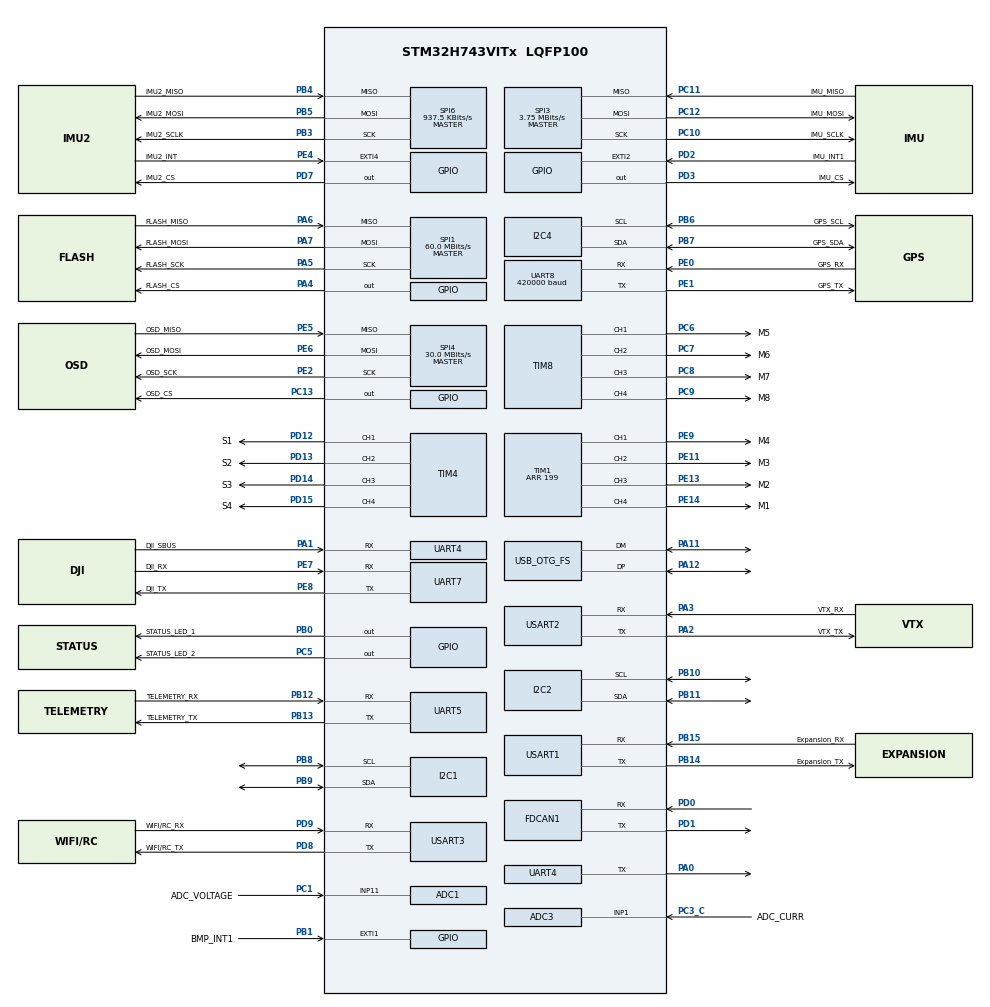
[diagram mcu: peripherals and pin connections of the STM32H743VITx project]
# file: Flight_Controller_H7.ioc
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ADC1.Channel-0\#ChannelRegularConversion=ADC_CHANNEL_11
ADC1.NbrOfConversionFlag=1
ADC1.OffsetNumber-0\#ChannelRegularConversion=ADC_OFFSET_NONE
ADC1.OffsetSignedSaturation-0\#ChannelRegularConversion=DISABLE
ADC1.Rank-0\#ChannelRegularConversion=1
ADC1.SamplingTime-0\#ChannelRegularConversion=ADC_SAMPLETIME_1CYCLE_5
ADC1.master=1
ADC3.Channel-0\#ChannelRegularConversion=ADC_CHANNEL_1
ADC3.NbrOfConversionFlag=1
ADC3.OffsetNumber-0\#ChannelRegularConversion=ADC_OFFSET_NONE
ADC3.OffsetSignedSaturation-0\#ChannelRegularConversion=DISABLE
ADC3.Rank-0\#ChannelRegularConversion=1
ADC3.SamplingTime-0\#ChannelRegularConversion=ADC_SAMPLETIME_1CYCLE_5
CORTEX_M7.default_mode_Activation=1
Dma.Request0=UART8_RX
Dma.Request1=TIM1_CH1
Dma.Request2=TIM1_CH2
Dma.Request3=TIM1_CH3
Dma.Request4=TIM1_CH4
Dma.Request5=TIM1_UP
Dma.TIM1_CH1.1.Direction=DMA_MEMORY_TO_PERIPH
Dma.TIM1_CH1.1.EventEnable=DISABLE
Dma.TIM1_CH1.1.FIFOMode=DMA_FIFOMODE_DISABLE
Dma.TIM1_CH1.1.Instance=DMA1_Stream1
Dma.TIM1_CH1.1.MemDataAlignment=DMA_MDATAALIGN_HALFWORD
Dma.TIM1_CH1.1.MemInc=DMA_MINC_ENABLE
Dma.TIM1_CH1.1.Mode=DMA_NORMAL
Dma.TIM1_CH1.1.PeriphDataAlignment=DMA_PDATAALIGN_HALFWORD
Dma.TIM1_CH1.1.PeriphInc=DMA_PINC_DISABLE
Dma.TIM1_CH1.1.Polarity=HAL_DMAMUX_REQ_GEN_RISING
Dma.TIM1_CH1.1.Priority=DMA_PRIORITY_HIGH
Dma.TIM1_CH1.1.RequestNumber=1
Dma.TIM1_CH1.1.SignalID=NONE
Dma.TIM1_CH1.1.SyncEnable=DISABLE
Dma.TIM1_CH1.1.SyncPolarity=HAL_DMAMUX_SYNC_NO_EVENT
Dma.TIM1_CH1.1.SyncRequestNumber=1
Dma.TIM1_CH1.1.SyncSignalID=NONE
Dma.TIM1_CH2.2.Direction=DMA_MEMORY_TO_PERIPH
Dma.TIM1_CH2.2.EventEnable=DISABLE
Dma.TIM1_CH2.2.FIFOMode=DMA_FIFOMODE_DISABLE
Dma.TIM1_CH2.2.Instance=DMA1_Stream2
Dma.TIM1_CH2.2.MemDataAlignment=DMA_MDATAALIGN_HALFWORD
Dma.TIM1_CH2.2.MemInc=DMA_MINC_ENABLE
Dma.TIM1_CH2.2.Mode=DMA_NORMAL
Dma.TIM1_CH2.2.PeriphDataAlignment=DMA_PDATAALIGN_HALFWORD
Dma.TIM1_CH2.2.PeriphInc=DMA_PINC_DISABLE
Dma.TIM1_CH2.2.Polarity=HAL_DMAMUX_REQ_GEN_RISING
Dma.TIM1_CH2.2.Priority=DMA_PRIORITY_HIGH
Dma.TIM1_CH2.2.RequestNumber=1
Dma.TIM1_CH2.2.SignalID=NONE
Dma.TIM1_CH2.2.SyncEnable=DISABLE
Dma.TIM1_CH2.2.SyncPolarity=HAL_DMAMUX_SYNC_NO_EVENT
Dma.TIM1_CH2.2.SyncRequestNumber=1
Dma.TIM1_CH2.2.SyncSignalID=NONE
Dma.TIM1_CH3.3.Direction=DMA_MEMORY_TO_PERIPH
Dma.TIM1_CH3.3.EventEnable=DISABLE
Dma.TIM1_CH3.3.FIFOMode=DMA_FIFOMODE_DISABLE
Dma.TIM1_CH3.3.Instance=DMA1_Stream3
Dma.TIM1_CH3.3.MemDataAlignment=DMA_MDATAALIGN_HALFWORD
Dma.TIM1_CH3.3.MemInc=DMA_MINC_ENABLE
Dma.TIM1_CH3.3.Mode=DMA_NORMAL
Dma.TIM1_CH3.3.PeriphDataAlignment=DMA_PDATAALIGN_HALFWORD
Dma.TIM1_CH3.3.PeriphInc=DMA_PINC_DISABLE
Dma.TIM1_CH3.3.Polarity=HAL_DMAMUX_REQ_GEN_RISING
Dma.TIM1_CH3.3.Priority=DMA_PRIORITY_HIGH
Dma.TIM1_CH3.3.RequestNumber=1
Dma.TIM1_CH3.3.SignalID=NONE
Dma.TIM1_CH3.3.SyncEnable=DISABLE
Dma.TIM1_CH3.3.SyncPolarity=HAL_DMAMUX_SYNC_NO_EVENT
Dma.TIM1_CH3.3.SyncRequestNumber=1
Dma.TIM1_CH3.3.SyncSignalID=NONE
Dma.TIM1_CH4.4.Direction=DMA_MEMORY_TO_PERIPH
Dma.TIM1_CH4.4.EventEnable=DISABLE
Dma.TIM1_CH4.4.FIFOMode=DMA_FIFOMODE_DISABLE
Dma.TIM1_CH4.4.Instance=DMA1_Stream4
Dma.TIM1_CH4.4.MemDataAlignment=DMA_MDATAALIGN_HALFWORD
Dma.TIM1_CH4.4.MemInc=DMA_MINC_ENABLE
Dma.TIM1_CH4.4.Mode=DMA_NORMAL
Dma.TIM1_CH4.4.PeriphDataAlignment=DMA_PDATAALIGN_HALFWORD
Dma.TIM1_CH4.4.PeriphInc=DMA_PINC_DISABLE
Dma.TIM1_CH4.4.Polarity=HAL_DMAMUX_REQ_GEN_RISING
Dma.TIM1_CH4.4.Priority=DMA_PRIORITY_HIGH
Dma.TIM1_CH4.4.RequestNumber=1
Dma.TIM1_CH4.4.SignalID=NONE
Dma.TIM1_CH4.4.SyncEnable=DISABLE
Dma.TIM1_CH4.4.SyncPolarity=HAL_DMAMUX_SYNC_NO_EVENT
Dma.TIM1_CH4.4.SyncRequestNumber=1
Dma.TIM1_CH4.4.SyncSignalID=NONE
Dma.TIM1_UP.5.Direction=DMA_MEMORY_TO_PERIPH
Dma.TIM1_UP.5.EventEnable=DISABLE
Dma.TIM1_UP.5.FIFOMode=DMA_FIFOMODE_DISABLE
Dma.TIM1_UP.5.Instance=DMA1_Stream5
Dma.TIM1_UP.5.MemDataAlignment=DMA_MDATAALIGN_HALFWORD
Dma.TIM1_UP.5.MemInc=DMA_MINC_ENABLE
Dma.TIM1_UP.5.Mode=DMA_NORMAL
Dma.TIM1_UP.5.PeriphDataAlignment=DMA_PDATAALIGN_HALFWORD
Dma.TIM1_UP.5.PeriphInc=DMA_PINC_DISABLE
Dma.TIM1_UP.5.Polarity=HAL_DMAMUX_REQ_GEN_RISING
Dma.TIM1_UP.5.Priority=DMA_PRIORITY_HIGH
Dma.TIM1_UP.5.RequestNumber=1
Dma.TIM1_UP.5.SignalID=NONE
Dma.TIM1_UP.5.SyncEnable=DISABLE
Dma.TIM1_UP.5.SyncPolarity=HAL_DMAMUX_SYNC_NO_EVENT
Dma.TIM1_UP.5.SyncRequestNumber=1
Dma.TIM1_UP.5.SyncSignalID=NONE
Dma.UART8_RX.0.Direction=DMA_PERIPH_TO_MEMORY
Dma.UART8_RX.0.EventEnable=DISABLE
Dma.UART8_RX.0.FIFOMode=DMA_FIFOMODE_DISABLE
Dma.UART8_RX.0.Instance=DMA1_Stream0
Dma.UART8_RX.0.MemDataAlignment=DMA_MDATAALIGN_BYTE
Dma.UART8_RX.0.MemInc=DMA_MINC_ENABLE
Dma.UART8_RX.0.Mode=DMA_CIRCULAR
Dma.UART8_RX.0.PeriphDataAlignment=DMA_PDATAALIGN_BYTE
Dma.UART8_RX.0.PeriphInc=DMA_PINC_DISABLE
Dma.UART8_RX.0.Polarity=HAL_DMAMUX_REQ_GEN_RISING
Dma.UART8_RX.0.Priority=DMA_PRIORITY_VERY_HIGH
Dma.UART8_RX.0.RequestNumber=1
Dma.UART8_RX.0.SignalID=NONE
Dma.UART8_RX.0.SyncEnable=DISABLE
Dma.UART8_RX.0.SyncPolarity=HAL_DMAMUX_SYNC_NO_EVENT
Dma.UART8_RX.0.SyncRequestNumber=1
Dma.UART8_RX.0.SyncSignalID=NONE
FDCAN1.CalculateBaudRateNominal=166666
FDCAN1.CalculateTimeBitNominal=6000
FDCAN1.CalculateTimeQuantumNominal=2000.0
FDCAN1.Mode=FDCAN_MODE_NORMAL
FDCAN1.RxBuffersNbr=0
FDCAN1.RxFifo0ElmtsNbr=0
FDCAN1.RxFifo1ElmtsNbr=0
FDCAN1.TxBuffersNbr=1
FDCAN1.TxElmtSize=FDCAN_DATA_BYTES_8
FDCAN1.TxFifoQueueElmtsNbr=31
I2C1.Timing=0x107075B0
I2C2.Timing=0x107075B0
I2C4.Timing=0x107075B0
Mcu.Family=STM32H7
Mcu.Name=STM32H743VITx
Mcu.Package=LQFP100
NVIC.DMA1_Stream0_IRQn=true\:0\:0\:false\:false\:true\:false\:true\:true
NVIC.DMA1_Stream1_IRQn=true\:0\:0\:false\:false\:true\:false\:true\:true
NVIC.DMA1_Stream2_IRQn=true\:0\:0\:false\:false\:true\:false\:true\:true
NVIC.DMA1_Stream3_IRQn=true\:0\:0\:false\:false\:true\:false\:true\:true
NVIC.DMA1_Stream4_IRQn=true\:0\:0\:false\:false\:true\:false\:true\:true
NVIC.DMA1_Stream5_IRQn=true\:0\:0\:false\:false\:true\:false\:true\:true
NVIC.OTG_FS_IRQn=true\:0\:0\:false\:false\:true\:false\:true\:true
NVIC.PriorityGroup=NVIC_PRIORITYGROUP_4
NVIC.TIM1_CC_IRQn=true\:0\:0\:false\:false\:true\:true\:true\:true
PA0.Mode=Asynchronous
PA0.PinAttribute=Free
PA0.Signal=UART4_TX
PA1.GPIO_Label=DJI_SBUS
PA1.Mode=Asynchronous
PA1.PinAttribute=Free
PA1.Signal=UART4_RX
PA11.Mode=Device_Only
PA11.PinAttribute=Free
PA11.Signal=USB_OTG_FS_DM
PA12.Mode=Device_Only
PA12.PinAttribute=Free
PA12.Signal=USB_OTG_FS_DP
PA13\ (JTMS/SWDIO).Mode=Serial_Wire
PA13\ (JTMS/SWDIO).PinAttribute=Free
PA13\ (JTMS/SWDIO).Signal=DEBUG_JTMS-SWDIO
PA14\ (JTCK/SWCLK).Mode=Serial_Wire
PA14\ (JTCK/SWCLK).PinAttribute=Free
PA14\ (JTCK/SWCLK).Signal=DEBUG_JTCK-SWCLK
PA2.GPIO_Label=VTX_TX
PA2.Mode=Asynchronous
PA2.PinAttribute=Free
PA2.Signal=USART2_TX
PA3.GPIO_Label=VTX_RX
PA3.Mode=Asynchronous
PA3.PinAttribute=Free
PA3.Signal=USART2_RX
PA4.GPIO_Label=FLASH_CS
PA4.PinAttribute=Free
PA4.Signal=GPIO_Output
PA5.GPIO_Label=FLASH_SCK
PA5.Mode=Full_Duplex_Master
PA5.PinAttribute=Free
PA5.Signal=SPI1_SCK
PA6.GPIO_Label=FLASH_MISO
PA6.Mode=Full_Duplex_Master
PA6.PinAttribute=Free
PA6.Signal=SPI1_MISO
PA7.GPIO_Label=FLASH_MOSI
PA7.Mode=Full_Duplex_Master
PA7.PinAttribute=Free
PA7.Signal=SPI1_MOSI
PB0.GPIO_Label=STATUS_LED_1
PB0.PinAttribute=Free
PB0.PinState=GPIO_PIN_SET
PB0.Signal=GPIO_Output
PB1.GPIO_Label=BMP_INT1
PB1.PinAttribute=Free
PB1.Signal=GPXTI1
PB10.Mode=I2C
PB10.PinAttribute=Free
PB10.Signal=I2C2_SCL
PB11.Mode=I2C
PB11.PinAttribute=Free
PB11.Signal=I2C2_SDA
PB12.GPIO_Label=TELEMETRY_RX
PB12.Mode=Asynchronous
PB12.PinAttribute=Free
PB12.Signal=UART5_RX
PB13.GPIO_Label=TELEMETRY_TX
PB13.Mode=Asynchronous
PB13.PinAttribute=Free
PB13.Signal=UART5_TX
PB14.GPIO_Label=Expansion_TX
PB14.Mode=Asynchronous
PB14.PinAttribute=Free
PB14.Signal=USART1_TX
PB15.GPIO_Label=Expansion_RX
PB15.Mode=Asynchronous
PB15.PinAttribute=Free
PB15.Signal=USART1_RX
PB3\ (JTDO/TRACESWO).GPIO_Label=IMU2_SCLK
PB3\ (JTDO/TRACESWO).Mode=Full_Duplex_Master
PB3\ (JTDO/TRACESWO).PinAttribute=Free
PB3\ (JTDO/TRACESWO).Signal=SPI6_SCK
PB4\ (NJTRST).GPIO_Label=IMU2_MISO
PB4\ (NJTRST).Mode=Full_Duplex_Master
PB4\ (NJTRST).PinAttribute=Free
PB4\ (NJTRST).Signal=SPI6_MISO
PB5.GPIO_Label=IMU2_MOSI
PB5.Mode=Full_Duplex_Master
PB5.PinAttribute=Free
PB5.Signal=SPI6_MOSI
PB6.GPIO_Label=GPS_SCL
PB6.Mode=I2C
PB6.PinAttribute=Free
PB6.Signal=I2C4_SCL
PB7.GPIO_Label=GPS_SDA
PB7.Mode=I2C
PB7.PinAttribute=Free
PB7.Signal=I2C4_SDA
PB8.Mode=I2C
PB8.PinAttribute=Free
PB8.Signal=I2C1_SCL
PB9.Mode=I2C
PB9.PinAttribute=Free
PB9.Signal=I2C1_SDA
PC1.GPIO_Label=ADC_VOLTAGE
PC1.PinAttribute=Free
PC1.Signal=ADCx_INP11
PC10.GPIO_Label=IMU_SCLK
PC10.Mode=Full_Duplex_Master
PC10.PinAttribute=Free
PC10.Signal=SPI3_SCK
PC11.GPIO_Label=IMU_MISO
PC11.Mode=Full_Duplex_Master
PC11.PinAttribute=Free
PC11.Signal=SPI3_MISO
PC12.GPIO_Label=IMU_MOSI
PC12.Mode=Full_Duplex_Master
PC12.PinAttribute=Free
PC12.Signal=SPI3_MOSI
PC13.GPIO_Label=OSD_CS
PC13.PinAttribute=Free
PC13.Signal=GPIO_Output
PC3_C.GPIO_Label=ADC_CURR
PC3_C.Mode=IN1-Single-Ended
PC3_C.PinAttribute=Free
PC3_C.Signal=ADC3_INP1
PC5.GPIO_Label=STATUS_LED_2
PC5.PinAttribute=Free
PC5.PinState=GPIO_PIN_SET
PC5.Signal=GPIO_Output
PC6.GPIO_Label=M5
PC6.PinAttribute=Free
PC6.Signal=S_TIM8_CH1
PC7.GPIO_Label=M6
PC7.PinAttribute=Free
PC7.Signal=S_TIM8_CH2
PC8.GPIO_Label=M7
PC8.PinAttribute=Free
PC8.Signal=S_TIM8_CH3
PC9.GPIO_Label=M8
PC9.PinAttribute=Free
PC9.Signal=S_TIM8_CH4
PD0.Mode=FDCAN_Activate
PD0.PinAttribute=Free
PD0.Signal=FDCAN1_RX
PD1.Mode=FDCAN_Activate
PD1.PinAttribute=Free
PD1.Signal=FDCAN1_TX
PD12.GPIO_Label=S1
PD12.PinAttribute=Free
PD12.Signal=S_TIM4_CH1
PD13.GPIO_Label=S2
PD13.PinAttribute=Free
PD13.Signal=S_TIM4_CH2
PD14.GPIO_Label=S3
PD14.PinAttribute=Free
PD14.Signal=S_TIM4_CH3
PD15.GPIO_Label=S4
PD15.PinAttribute=Free
PD15.Signal=S_TIM4_CH4
PD2.GPIO_Label=IMU_INT1
PD2.PinAttribute=Free
PD2.Signal=GPXTI2
PD3.GPIO_Label=IMU_CS
PD3.PinAttribute=Free
PD3.Signal=GPIO_Output
PD7.GPIO_Label=IMU2_CS
PD7.PinAttribute=Free
PD7.Signal=GPIO_Output
PD8.GPIO_Label=WIFI/RC_TX
PD8.Mode=Asynchronous
PD8.PinAttribute=Free
PD8.Signal=USART3_TX
PD9.GPIO_Label=WIFI/RC_RX
PD9.Mode=Asynchronous
PD9.PinAttribute=Free
PD9.Signal=USART3_RX
PE0.GPIO_Label=GPS_RX
PE0.Mode=Asynchronous
PE0.PinAttribute=Free
PE0.Signal=UART8_RX
PE1.GPIO_Label=GPS_TX
PE1.Mode=Asynchronous
PE1.PinAttribute=Free
PE1.Signal=UART8_TX
PE11.GPIO_Label=M3
PE11.PinAttribute=Free
PE11.Signal=S_TIM1_CH2
PE13.GPIO_Label=M2
PE13.PinAttribute=Free
PE13.Signal=S_TIM1_CH3
PE14.GPIO_Label=M1
PE14.PinAttribute=Free
PE14.Signal=S_TIM1_CH4
PE2.GPIO_Label=OSD_SCK
PE2.Mode=Full_Duplex_Master
PE2.PinAttribute=Free
PE2.Signal=SPI4_SCK
PE4.GPIO_Label=IMU2_INT
PE4.PinAttribute=Free
PE4.Signal=GPXTI4
PE5.GPIO_Label=OSD_MISO
PE5.Mode=Full_Duplex_Master
PE5.PinAttribute=Free
PE5.Signal=SPI4_MISO
PE6.GPIO_Label=OSD_MOSI
PE6.Mode=Full_Duplex_Master
PE6.PinAttribute=Free
PE6.Signal=SPI4_MOSI
PE7.GPIO_Label=DJI_RX
PE7.Mode=Asynchronous
PE7.PinAttribute=Free
PE7.Signal=UART7_RX
PE8.GPIO_Label=DJI_TX
PE8.Mode=Asynchronous
PE8.PinAttribute=Free
PE8.Signal=UART7_TX
PE9.GPIO_Label=M4
PE9.PinAttribute=Free
PE9.Signal=S_TIM1_CH1
PH0-OSC_IN\ (PH0).Mode=HSE-External-Clock-Source
PH0-OSC_IN\ (PH0).PinAttribute=Free
PH0-OSC_IN\ (PH0).Signal=RCC_OSC_IN
ProjectManager.HeapSize=0x200
ProjectManager.StackSize=0x400
ProjectManager.TargetToolchain=STM32CubeIDE
RCC.ADCFreq_Value=76000000
RCC.APB1Freq_Value=60000000
RCC.APB2Freq_Value=60000000
RCC.APB3Freq_Value=120000000
RCC.APB4Freq_Value=60000000
RCC.CortexFreq_Value=240000000
RCC.D2PPRE1=RCC_APB1_DIV2
RCC.D2PPRE2=RCC_APB2_DIV2
RCC.D3PPRE=RCC_APB4_DIV2
RCC.DIVM1=1
RCC.DIVM2=1
RCC.DIVN1=60
RCC.DIVN2=19
RCC.DIVQ1=4
RCC.DIVR1=4
RCC.EnbaleCSS=true
RCC.FDCANCLockSelection=RCC_FDCANCLKSOURCE_HSE
RCC.FLatency-AdvancedSettings=FLASH_LATENCY_0
RCC.HCLKFreq_Value=120000000
RCC.HPRE=RCC_HCLK_DIV2
RCC.HSE_VALUE=8000000
RCC.PLL1_VCI_Range-AdvancedSettings=RCC_PLL1VCIRANGE_0
RCC.PLL1_VCO_SEL-AdvancedSettings=RCC_PLL1VCOMEDIUM
RCC.PLL2FRACN=0
RCC.PLL2_VCI_Range-AdvancedSettings=RCC_PLL2VCIRANGE_0
RCC.PLL2_VCO_SEL-AdvancedSettings=RCC_PLL2VCOMEDIUM
RCC.PLL3_VCI_Range-AdvancedSettings=RCC_PLL3VCIRANGE_0
RCC.PLL3_VCO_SEL-AdvancedSettings=RCC_PLL3VCOMEDIUM
RCC.PLLFRACN=0
RCC.PLLSourceVirtual=RCC_PLLSOURCE_HSE
RCC.PREFETCH_ENABLE=1
RCC.SYSCLKFreq_VALUE=240000000
RCC.SYSCLKSource=RCC_SYSCLKSOURCE_PLLCLK
RCC.USBCLockSelection=RCC_USBCLKSOURCE_HSI48
RCC.USBFreq_Value=48000000
SH.ADCx_INP11.0=ADC1_INP11,IN11-Single-Ended
SH.S_TIM1_CH1.0=TIM1_CH1,PWM Generation1 CH1
SH.S_TIM1_CH2.0=TIM1_CH2,PWM Generation2 CH2
SH.S_TIM1_CH3.0=TIM1_CH3,PWM Generation3 CH3
SH.S_TIM1_CH4.0=TIM1_CH4,PWM Generation4 CH4
SH.S_TIM4_CH1.0=TIM4_CH1,PWM Generation1 CH1
SH.S_TIM4_CH2.0=TIM4_CH2,PWM Generation2 CH2
SH.S_TIM4_CH3.0=TIM4_CH3,PWM Generation3 CH3
SH.S_TIM4_CH4.0=TIM4_CH4,PWM Generation4 CH4
SH.S_TIM8_CH1.0=TIM8_CH1,PWM Generation1 CH1
SH.S_TIM8_CH2.0=TIM8_CH2,PWM Generation2 CH2
SH.S_TIM8_CH3.0=TIM8_CH3,PWM Generation3 CH3
SH.S_TIM8_CH4.0=TIM8_CH4,Output Compare4 CH4
SPI1.BaudRatePrescaler=SPI_BAUDRATEPRESCALER_2
SPI1.CalculateBaudRate=60.0 MBits/s
SPI1.Direction=SPI_DIRECTION_2LINES
SPI1.Mode=SPI_MODE_MASTER
SPI1.VirtualType=VM_MASTER
SPI3.BaudRatePrescaler=SPI_BAUDRATEPRESCALER_32
SPI3.CLKPhase=SPI_PHASE_1EDGE
SPI3.CLKPolarity=SPI_POLARITY_LOW
SPI3.CalculateBaudRate=3.75 MBits/s
SPI3.DataSize=SPI_DATASIZE_8BIT
SPI3.Direction=SPI_DIRECTION_2LINES
SPI3.Mode=SPI_MODE_MASTER
SPI3.VirtualType=VM_MASTER
SPI4.CalculateBaudRate=30.0 MBits/s
SPI4.Direction=SPI_DIRECTION_2LINES
SPI4.Mode=SPI_MODE_MASTER
SPI4.VirtualType=VM_MASTER
SPI6.BaudRatePrescaler=SPI_BAUDRATEPRESCALER_64
SPI6.CLKPhase=SPI_PHASE_2EDGE
SPI6.CLKPolarity=SPI_POLARITY_HIGH
SPI6.CalculateBaudRate=937.5 KBits/s
SPI6.DataSize=SPI_DATASIZE_8BIT
SPI6.Direction=SPI_DIRECTION_2LINES
SPI6.Mode=SPI_MODE_MASTER
SPI6.VirtualType=VM_MASTER
TIM1.Channel-PWM\ Generation1\ CH1=TIM_CHANNEL_1
TIM1.Channel-PWM\ Generation2\ CH2=TIM_CHANNEL_2
TIM1.Channel-PWM\ Generation3\ CH3=TIM_CHANNEL_3
TIM1.Channel-PWM\ Generation4\ CH4=TIM_CHANNEL_4
TIM1.Period=199
TIM4.Channel-PWM\ Generation1\ CH1=TIM_CHANNEL_1
TIM4.Channel-PWM\ Generation2\ CH2=TIM_CHANNEL_2
TIM4.Channel-PWM\ Generation3\ CH3=TIM_CHANNEL_3
TIM4.Channel-PWM\ Generation4\ CH4=TIM_CHANNEL_4
TIM8.Channel-Output\ Compare4\ CH4=TIM_CHANNEL_4
TIM8.Channel-PWM\ Generation1\ CH1=TIM_CHANNEL_1
TIM8.Channel-PWM\ Generation2\ CH2=TIM_CHANNEL_2
TIM8.Channel-PWM\ Generation3\ CH3=TIM_CHANNEL_3
UART4.BaudRate=100000
UART4.Parity=PARITY_EVEN
UART4.RxPinLevelInvertParam=UART_ADVFEATURE_RXINV_ENABLE
UART4.StopBits=UART_STOPBITS_2
UART4.WordLength=WORDLENGTH_9B
UART8.BaudRate=420000
UART8.DMADisableonRxErrorParam=UART_ADVFEATURE_DMA_DISABLEONRXERROR
UART8.OverSampling=UART_OVERSAMPLING_8
UART8.SwapParam=UART_ADVFEATURE_SWAP_DISABLE
USART1.VirtualMode-Asynchronous=VM_ASYNC
USART2.VirtualMode-Asynchronous=VM_ASYNC
USART3.VirtualMode-Asynchronous=VM_ASYNC
USB_DEVICE.CLASS_NAME_FS=CDC
USB_DEVICE.VirtualMode-CDC_FS=Cdc
USB_DEVICE.VirtualModeFS=Cdc_FS
USB_OTG_FS.VirtualMode=Device_Only
VP_ADC3_Vref_Input.Mode=IN-Vrefint
VP_MEMORYMAP_VS_MEMORYMAP.Mode=CurAppReg
VP_TIM1_VS_ClockSourceINT.Mode=Internal
VP_TIM2_VS_ClockSourceINT.Mode=Internal
VP_TIM3_VS_ClockSourceINT.Mode=Internal
VP_TIM4_VS_ClockSourceINT.Mode=Internal
VP_TIM5_VS_ClockSourceINT.Mode=Internal
VP_USB_DEVICE_VS_USB_DEVICE_CDC_FS.Mode=CDC_FS
board=custom

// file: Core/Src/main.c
/* USER CODE BEGIN Header */
/**
  ******************************************************************************
  * @file           : main.c
  * @brief          : Main program body
  ******************************************************************************
  * @attention
  *
  * Copyright (c) 2025 STMicroelectronics.
  * All rights reserved.
  *
  * This software is licensed under terms that can be found in the LICENSE file
  * in the root directory of this software component.
  * If no LICENSE file comes with this software, it is provided AS-IS.
  *
  ******************************************************************************
  */
/* USER CODE END Header */
#include "main.h"
#include "usb_device.h"

/* USER CODE BEGIN Includes */
#include "icm42688p.h"
#include "dshot.h"
#include "motor_mix.h"
#include "crsf.h"
#include "pid.h"
/* USER CODE END Includes */

/* USER CODE BEGIN PD */

/*
 * ── Stick → rate setpoints ───────────────────────────────────────────────────
 * How fast (deg/s) the quad rotates at full stick deflection.
 * Conservative for a first flight — increase after confirming stability.
 */
#define MAX_ROLL_RATE    200.0f
#define MAX_PITCH_RATE   200.0f
#define MAX_YAW_RATE     150.0f

/*
 * ── Gyro axis sign correction ────────────────────────────────────────────────
 * Verify by moving the board and watching gyro values in the debugger.
 * Convention:
 *   Roll board right   → gyro_roll  must be POSITIVE  (flip GYRO_SIGN_ROLL  if not)
 *   Pitch nose up      → gyro_pitch must be POSITIVE  (flip GYRO_SIGN_PITCH if not)
 *   Yaw nose clockwise → gyro_yaw   must be POSITIVE  (flip GYRO_SIGN_YAW   if not)
 */
#define GYRO_SIGN_ROLL    1
#define GYRO_SIGN_PITCH   1
#define GYRO_SIGN_YAW     1

/*
 * ── Arming ───────────────────────────────────────────────────────────────────
 * AUX1 switch must be HIGH and throttle below ARM_THR_MAX for ARM_HOLD_MS
 * before the quad arms. Prevents accidental arming.
 */
#define ARM_THR_MAX       5.0f    /* % throttle ceiling for arming */
#define ARM_HOLD_MS       500U    /* ms to hold conditions before arm */

/*
 * ── PID gains ────────────────────────────────────────────────────────────────
 * D = 0 for first flight. No software gyro LPF yet, so D would amplify noise.
 * Add D (e.g. ROLL_KD 0.000025f) only after P+I is confirmed flyable.
 *
 * If quad oscillates fast  → reduce Kp 20%
 * If quad drifts slowly    → increase Ki 20%
 * If quad feels very lazy  → increase Kp 20%
 */
#define ROLL_KP    0.0015f
#define ROLL_KI    0.002f
#define ROLL_KD    0.0f

#define PITCH_KP   0.0015f
#define PITCH_KI   0.002f
#define PITCH_KD   0.0f

#define YAW_KP     0.0012f
#define YAW_KI     0.004f
#define YAW_KD     0.0f

/* USER CODE END PD */

ADC_HandleTypeDef hadc1;
ADC_HandleTypeDef hadc3;

FDCAN_HandleTypeDef hfdcan1;

I2C_HandleTypeDef hi2c1;
I2C_HandleTypeDef hi2c2;
I2C_HandleTypeDef hi2c4;

SPI_HandleTypeDef hspi1;
SPI_HandleTypeDef hspi3;
SPI_HandleTypeDef hspi4;
SPI_HandleTypeDef hspi6;

TIM_HandleTypeDef htim1;
TIM_HandleTypeDef htim2;
TIM_HandleTypeDef htim3;
TIM_HandleTypeDef htim4;
TIM_HandleTypeDef htim5;
TIM_HandleTypeDef htim8;
DMA_HandleTypeDef hdma_tim1_ch1;
DMA_HandleTypeDef hdma_tim1_ch2;
DMA_HandleTypeDef hdma_tim1_ch3;
DMA_HandleTypeDef hdma_tim1_ch4;
DMA_HandleTypeDef hdma_tim1_up;

UART_HandleTypeDef huart4;
UART_HandleTypeDef huart5;
UART_HandleTypeDef huart7;
UART_HandleTypeDef huart8;
UART_HandleTypeDef huart1;
UART_HandleTypeDef huart2;
UART_HandleTypeDef huart3;
DMA_HandleTypeDef hdma_uart8_rx;

/* USER CODE BEGIN PV */
static PID_t             pid_roll, pid_pitch, pid_yaw;
static ICM42688P_Data_t  icm_data;
static bool              armed         = false;
static uint32_t          arm_timer     = 0;  /* HAL_GetTick() stamp when arm conditions first met */
static uint32_t          loop_last_cnt = 0;  /* TIM2 CNT snapshot for 1 kHz gate */
/* USER CODE END PV */

void SystemClock_Config(void);
void PeriphCommonClock_Config(void);
static void MPU_Config(void);
static void MX_GPIO_Init(void);
static void MX_DMA_Init(void);
static void MX_I2C1_Init(void);
static void MX_I2C2_Init(void);
static void MX_SPI1_Init(void);
static void MX_SPI3_Init(void);
static void MX_SPI4_Init(void);
static void MX_SPI6_Init(void);
static void MX_TIM1_Init(void);
static void MX_TIM2_Init(void);
static void MX_TIM3_Init(void);
static void MX_TIM4_Init(void);
static void MX_USART1_UART_Init(void);
static void MX_USART2_UART_Init(void);
static void MX_USART3_UART_Init(void);
static void MX_ADC3_Init(void);
static void MX_TIM5_Init(void);
static void MX_UART8_Init(void);
static void MX_UART7_Init(void);
static void MX_FDCAN1_Init(void);
static void MX_I2C4_Init(void);
static void MX_TIM8_Init(void);
static void MX_UART4_Init(void);
static void MX_UART5_Init(void);
static void MX_ADC1_Init(void);

int main(void)
{

  /* MPU Configuration--------------------------------------------------------*/
  MPU_Config();

  /* MCU Configuration--------------------------------------------------------*/

  /* Reset of all peripherals, Initializes the Flash interface and the Systick. */
  HAL_Init();

  /* Configure the system clock */
  SystemClock_Config();

  /* Configure the peripherals common clocks */
  PeriphCommonClock_Config();

  /* Initialize all configured peripherals */
  MX_GPIO_Init();
  MX_DMA_Init();
  MX_I2C1_Init();
  MX_I2C2_Init();
  MX_SPI1_Init();
  MX_SPI3_Init();
  MX_SPI4_Init();
  MX_SPI6_Init();
  MX_TIM1_Init();
  MX_TIM2_Init();
  MX_TIM3_Init();
  MX_TIM4_Init();
  MX_USART1_UART_Init();
  MX_USART2_UART_Init();
  MX_USART3_UART_Init();
  MX_ADC3_Init();
  MX_TIM5_Init();
  MX_UART8_Init();
  MX_UART7_Init();
  MX_FDCAN1_Init();
  MX_I2C4_Init();
  MX_TIM8_Init();
  MX_UART4_Init();
  MX_UART5_Init();
  MX_ADC1_Init();
  MX_USB_DEVICE_Init();
  /* USER CODE BEGIN 2 */

  /* ── DSHOT on TIM1 (M4=PE9, M3=PE11, M2=PE13, M1=PE14) ──────────────── */
  DSHOT_Init(&htim1);

  /* ── CRSF receiver on UART8 (PE0=RX, PE1=TX) at 420 kbaud ───────────── */
  CRSF_Init(&huart8);

  /* ── ICM42688P on SPI6 (PB3/4/5), CS=PD7 ────────────────────────────── *
   * Blink LED1 fast until sensor responds. LED1 steady ON = IMU OK.        *
   * If LED1 never stops blinking: check SPI6 wiring / CS pin / power.      */
  while (ICM42688P_Init(&hspi6) != ICM42688P_OK) {
      HAL_GPIO_TogglePin(STATUS_LED_1_GPIO_Port, STATUS_LED_1_Pin);
      HAL_Delay(50);
  }
  HAL_GPIO_WritePin(STATUS_LED_1_GPIO_Port, STATUS_LED_1_Pin, GPIO_PIN_RESET); /* steady ON */

  /* ── PIDs ─────────────────────────────────────────────────────────────── */
  PID_Init(&pid_roll,  ROLL_KP,  ROLL_KI,  ROLL_KD,  0.30f);
  PID_Init(&pid_pitch, PITCH_KP, PITCH_KI, PITCH_KD, 0.30f);
  PID_Init(&pid_yaw,   YAW_KP,   YAW_KI,   YAW_KD,   0.40f);

  /* ── ESC startup ─────────────────────────────────────────────────────── *
   * BLHeli32 needs DSHOT throttle=0 for ~2 s before it considers itself    *
   * armed and ready to accept real throttle commands. 3 s is generous.      */
  {
      uint32_t t0 = HAL_GetTick();
      while (HAL_GetTick() - t0 < 3000U) {
          MOTOR_Disarm();
          HAL_Delay(10);
      }
  }

  /* ── Start TIM2 for precise 1kHz loop gate ───────────────────────────── *
   * TIM2 is a 32-bit free-run counter at 120 MHz (TIM2 clock = 2×APB1).   *
   * 120 000 ticks = 1 ms exactly.                                           */
  HAL_TIM_Base_Start(&htim2);
  loop_last_cnt = TIM2->CNT;

  /* USER CODE END 2 */

  /* Infinite loop */
  /* USER CODE BEGIN WHILE */
  while (1)
  {
    /* ── 1 kHz loop gate ────────────────────────────────────────────────── *
     * TIM2 is a 32-bit free-run counter at 120 MHz (HCLK).                  *
     * 120 000 ticks = exactly 1 ms.  Spin here until the tick arrives.       */
    uint32_t now = TIM2->CNT;
    if ((uint32_t)(now - loop_last_cnt) < 120000U) {
        continue;
    }
    loop_last_cnt = now;
    const float dt = 0.001f;   /* seconds — matches the gate above */

    /* ── Drain CRSF circular-DMA buffer ────────────────────────────────── *
     * CRSF runs ~150 Hz; we call this at 1 kHz so we never miss a frame.    */
    CRSF_Process();

    /* ── Read IMU (SPI6, blocking, ~20 µs) ─────────────────────────────── */
    ICM42688P_ReadAll(&hspi6, &icm_data);

    /* ── Gyro axis sign correction ──────────────────────────────────────── *
     * Before first flight, hold the board and rotate it slowly:              *
     *   Roll board clockwise (right wing down) → gyro_roll  must be +       *
     *   Pitch nose up                          → gyro_pitch must be +       *
     *   Yaw nose clockwise                     → gyro_yaw   must be +       *
     * Flip the matching GYRO_SIGN_* define in PD if the sign is wrong.      */
    float gyro_roll  = (float)GYRO_SIGN_ROLL  * icm_data.gyro_dps.x;
    float gyro_pitch = (float)GYRO_SIGN_PITCH * icm_data.gyro_dps.y;
    float gyro_yaw   = (float)GYRO_SIGN_YAW   * icm_data.gyro_dps.z;

    /* ── Failsafe / forced disarm ───────────────────────────────────────── *
     * Disarm immediately if CRSF link is lost or AUX1 goes LOW.             */
    if (crsf_data.failsafe || !crsf_data.armed) {
        if (armed) {
            armed = false;
            PID_Reset(&pid_roll);
            PID_Reset(&pid_pitch);
            PID_Reset(&pid_yaw);
        }
        arm_timer = 0;
    }

    /* ── Arm logic ──────────────────────────────────────────────────────── *
     * Conditions: AUX1 HIGH + throttle < ARM_THR_MAX + link alive.          *
     * All three must hold for ARM_HOLD_MS before armed becomes true.         *
     * Any condition failing resets the timer → must start over.             */
    if (!armed
        && crsf_data.armed
        && (crsf_data.throttle < ARM_THR_MAX)
        && !crsf_data.failsafe)
    {
        if (arm_timer == 0U) {
            arm_timer = HAL_GetTick();
        } else if ((HAL_GetTick() - arm_timer) >= ARM_HOLD_MS) {
            armed     = true;
            arm_timer = 0U;
        }
    } else if (!crsf_data.armed || (crsf_data.throttle >= ARM_THR_MAX)) {
        arm_timer = 0U;   /* abort countdown */
    }

    /* ── Flight loop ────────────────────────────────────────────────────── */
    if (armed) {

        /* Stick position → rate setpoints (deg/s)
         * CRSF roll/pitch/yaw are ±100.0 at full deflection. */
        float sp_roll  = (crsf_data.roll  / 100.0f) * MAX_ROLL_RATE;
        float sp_pitch = (crsf_data.pitch / 100.0f) * MAX_PITCH_RATE;
        float sp_yaw   = (crsf_data.yaw   / 100.0f) * MAX_YAW_RATE;

        /* Rate PIDs — output is normalised ≈ ±1.0 for MOTOR_Mix */
        float out_roll  = PID_Update(&pid_roll,  sp_roll,  gyro_roll,  dt);
        float out_pitch = PID_Update(&pid_pitch, sp_pitch, gyro_pitch, dt);
        float out_yaw   = PID_Update(&pid_yaw,   sp_yaw,  gyro_yaw,   dt);

        /* Throttle: CRSF 0–100 → MOTOR_Mix 0–1 */
        float thr = crsf_data.throttle / 100.0f;

        MOTOR_Mix(thr, out_roll, out_pitch, out_yaw);

    } else {
        MOTOR_Disarm();
    }

    /* USER CODE END WHILE */

  }
}

void SystemClock_Config(void)
{
  RCC_OscInitTypeDef RCC_OscInitStruct = {0};
  RCC_ClkInitTypeDef RCC_ClkInitStruct = {0};

  /** Supply configuration update enable
  */
  HAL_PWREx_ConfigSupply(PWR_LDO_SUPPLY);

  /** Configure the main internal regulator output voltage
  */
  __HAL_PWR_VOLTAGESCALING_CONFIG(PWR_REGULATOR_VOLTAGE_SCALE2);

  while(!__HAL_PWR_GET_FLAG(PWR_FLAG_VOSRDY)) {}

  /** Initializes the RCC Oscillators according to the specified parameters
  * in the RCC_OscInitTypeDef structure.
  */
  RCC_OscInitStruct.OscillatorType = RCC_OSCILLATORTYPE_HSI48|RCC_OSCILLATORTYPE_HSE;
  RCC_OscInitStruct.HSEState = RCC_HSE_BYPASS;
  RCC_OscInitStruct.HSI48State = RCC_HSI48_ON;
  RCC_OscInitStruct.PLL.PLLState = RCC_PLL_ON;
  RCC_OscInitStruct.PLL.PLLSource = RCC_PLLSOURCE_HSE;
  RCC_OscInitStruct.PLL.PLLM = 1;
  RCC_OscInitStruct.PLL.PLLN = 60;
  RCC_OscInitStruct.PLL.PLLP = 2;
  RCC_OscInitStruct.PLL.PLLQ = 4;
  RCC_OscInitStruct.PLL.PLLR = 4;
  RCC_OscInitStruct.PLL.PLLRGE = RCC_PLL1VCIRANGE_3;
  RCC_OscInitStruct.PLL.PLLVCOSEL = RCC_PLL1VCOWIDE;
  RCC_OscInitStruct.PLL.PLLFRACN = 0;
  if (HAL_RCC_OscConfig(&RCC_OscInitStruct) != HAL_OK)
  {
    Error_Handler();
  }

  /** Initializes the CPU, AHB and APB buses clocks
  */
  RCC_ClkInitStruct.ClockType = RCC_CLOCKTYPE_HCLK|RCC_CLOCKTYPE_SYSCLK
                              |RCC_CLOCKTYPE_PCLK1|RCC_CLOCKTYPE_PCLK2
                              |RCC_CLOCKTYPE_D3PCLK1|RCC_CLOCKTYPE_D1PCLK1;
  RCC_ClkInitStruct.SYSCLKSource = RCC_SYSCLKSOURCE_PLLCLK;
  RCC_ClkInitStruct.SYSCLKDivider = RCC_SYSCLK_DIV1;
  RCC_ClkInitStruct.AHBCLKDivider = RCC_HCLK_DIV2;
  RCC_ClkInitStruct.APB3CLKDivider = RCC_APB3_DIV1;
  RCC_ClkInitStruct.APB1CLKDivider = RCC_APB1_DIV2;
  RCC_ClkInitStruct.APB2CLKDivider = RCC_APB2_DIV2;
  RCC_ClkInitStruct.APB4CLKDivider = RCC_APB4_DIV2;

  if (HAL_RCC_ClockConfig(&RCC_ClkInitStruct, FLASH_LATENCY_2) != HAL_OK)
  {
    Error_Handler();
  }

  /** Enables the Clock Security System
  */
  HAL_RCC_EnableCSS();
}

void PeriphCommonClock_Config(void)
{
  RCC_PeriphCLKInitTypeDef PeriphClkInitStruct = {0};

  /** Initializes the peripherals clock
  */
  PeriphClkInitStruct.PeriphClockSelection = RCC_PERIPHCLK_ADC;
  PeriphClkInitStruct.PLL2.PLL2M = 1;
  PeriphClkInitStruct.PLL2.PLL2N = 19;
  PeriphClkInitStruct.PLL2.PLL2P = 2;
  PeriphClkInitStruct.PLL2.PLL2Q = 2;
  PeriphClkInitStruct.PLL2.PLL2R = 2;
  PeriphClkInitStruct.PLL2.PLL2RGE = RCC_PLL2VCIRANGE_3;
  PeriphClkInitStruct.PLL2.PLL2VCOSEL = RCC_PLL2VCOMEDIUM;
  PeriphClkInitStruct.PLL2.PLL2FRACN = 0;
  PeriphClkInitStruct.AdcClockSelection = RCC_ADCCLKSOURCE_PLL2;
  if (HAL_RCCEx_PeriphCLKConfig(&PeriphClkInitStruct) != HAL_OK)
  {
    Error_Handler();
  }
}

static void MX_ADC1_Init(void)
{

  ADC_MultiModeTypeDef multimode = {0};
  ADC_ChannelConfTypeDef sConfig = {0};

  /** Common config
  */
  hadc1.Instance = ADC1;
  hadc1.Init.ClockPrescaler = ADC_CLOCK_ASYNC_DIV2;
  hadc1.Init.Resolution = ADC_RESOLUTION_16B;
  hadc1.Init.ScanConvMode = ADC_SCAN_DISABLE;
  hadc1.Init.EOCSelection = ADC_EOC_SINGLE_CONV;
  hadc1.Init.LowPowerAutoWait = DISABLE;
  hadc1.Init.ContinuousConvMode = DISABLE;
  hadc1.Init.NbrOfConversion = 1;
  hadc1.Init.DiscontinuousConvMode = DISABLE;
  hadc1.Init.ExternalTrigConv = ADC_SOFTWARE_START;
  hadc1.Init.ExternalTrigConvEdge = ADC_EXTERNALTRIGCONVEDGE_NONE;
  hadc1.Init.ConversionDataManagement = ADC_CONVERSIONDATA_DR;
  hadc1.Init.Overrun = ADC_OVR_DATA_PRESERVED;
  hadc1.Init.LeftBitShift = ADC_LEFTBITSHIFT_NONE;
  hadc1.Init.OversamplingMode = DISABLE;
  hadc1.Init.Oversampling.Ratio = 1;
  if (HAL_ADC_Init(&hadc1) != HAL_OK)
  {
    Error_Handler();
  }

  /** Configure the ADC multi-mode
  */
  multimode.Mode = ADC_MODE_INDEPENDENT;
  if (HAL_ADCEx_MultiModeConfigChannel(&hadc1, &multimode) != HAL_OK)
  {
    Error_Handler();
  }

  /** Configure Regular Channel
  */
  sConfig.Channel = ADC_CHANNEL_11;
  sConfig.Rank = ADC_REGULAR_RANK_1;
  sConfig.SamplingTime = ADC_SAMPLETIME_1CYCLE_5;
  sConfig.SingleDiff = ADC_SINGLE_ENDED;
  sConfig.OffsetNumber = ADC_OFFSET_NONE;
  sConfig.Offset = 0;
  sConfig.OffsetSignedSaturation = DISABLE;
  if (HAL_ADC_ConfigChannel(&hadc1, &sConfig) != HAL_OK)
  {
    Error_Handler();
  }

}

static void MX_ADC3_Init(void)
{

  ADC_ChannelConfTypeDef sConfig = {0};

  /** Common config
  */
  hadc3.Instance = ADC3;
  hadc3.Init.Resolution = ADC_RESOLUTION_16B;
  hadc3.Init.ScanConvMode = ADC_SCAN_DISABLE;
  hadc3.Init.EOCSelection = ADC_EOC_SINGLE_CONV;
  hadc3.Init.LowPowerAutoWait = DISABLE;
  hadc3.Init.ContinuousConvMode = DISABLE;
  hadc3.Init.NbrOfConversion = 1;
  hadc3.Init.DiscontinuousConvMode = DISABLE;
  hadc3.Init.ExternalTrigConv = ADC_SOFTWARE_START;
  hadc3.Init.ExternalTrigConvEdge = ADC_EXTERNALTRIGCONVEDGE_NONE;
  hadc3.Init.ConversionDataManagement = ADC_CONVERSIONDATA_DR;
  hadc3.Init.Overrun = ADC_OVR_DATA_PRESERVED;
  hadc3.Init.LeftBitShift = ADC_LEFTBITSHIFT_NONE;
  hadc3.Init.OversamplingMode = DISABLE;
  hadc3.Init.Oversampling.Ratio = 1;
  if (HAL_ADC_Init(&hadc3) != HAL_OK)
  {
    Error_Handler();
  }

  /** Configure Regular Channel
  */
  sConfig.Channel = ADC_CHANNEL_1;
  sConfig.Rank = ADC_REGULAR_RANK_1;
  sConfig.SamplingTime = ADC_SAMPLETIME_1CYCLE_5;
  sConfig.SingleDiff = ADC_SINGLE_ENDED;
  sConfig.OffsetNumber = ADC_OFFSET_NONE;
  sConfig.Offset = 0;
  sConfig.OffsetSignedSaturation = DISABLE;
  if (HAL_ADC_ConfigChannel(&hadc3, &sConfig) != HAL_OK)
  {
    Error_Handler();
  }

}

static void MX_FDCAN1_Init(void)
{

  hfdcan1.Instance = FDCAN1;
  hfdcan1.Init.FrameFormat = FDCAN_FRAME_CLASSIC;
  hfdcan1.Init.Mode = FDCAN_MODE_NORMAL;
  hfdcan1.Init.AutoRetransmission = DISABLE;
  hfdcan1.Init.TransmitPause = DISABLE;
  hfdcan1.Init.ProtocolException = DISABLE;
  hfdcan1.Init.NominalPrescaler = 16;
  hfdcan1.Init.NominalSyncJumpWidth = 1;
  hfdcan1.Init.NominalTimeSeg1 = 1;
  hfdcan1.Init.NominalTimeSeg2 = 1;
  hfdcan1.Init.DataPrescaler = 1;
  hfdcan1.Init.DataSyncJumpWidth = 1;
  hfdcan1.Init.DataTimeSeg1 = 1;
  hfdcan1.Init.DataTimeSeg2 = 1;
  hfdcan1.Init.MessageRAMOffset = 0;
  hfdcan1.Init.StdFiltersNbr = 0;
  hfdcan1.Init.ExtFiltersNbr = 0;
  hfdcan1.Init.RxFifo0ElmtsNbr = 0;
  hfdcan1.Init.RxFifo0ElmtSize = FDCAN_DATA_BYTES_8;
  hfdcan1.Init.RxFifo1ElmtsNbr = 0;
  hfdcan1.Init.RxFifo1ElmtSize = FDCAN_DATA_BYTES_8;
  hfdcan1.Init.RxBuffersNbr = 0;
  hfdcan1.Init.RxBufferSize = FDCAN_DATA_BYTES_8;
  hfdcan1.Init.TxEventsNbr = 0;
  hfdcan1.Init.TxBuffersNbr = 1;
  hfdcan1.Init.TxFifoQueueElmtsNbr = 31;
  hfdcan1.Init.TxFifoQueueMode = FDCAN_TX_FIFO_OPERATION;
  hfdcan1.Init.TxElmtSize = FDCAN_DATA_BYTES_8;
  if (HAL_FDCAN_Init(&hfdcan1) != HAL_OK)
  {
    Error_Handler();
  }

}

static void MX_I2C1_Init(void)
{

  hi2c1.Instance = I2C1;
  hi2c1.Init.Timing = 0x107075B0;
  hi2c1.Init.OwnAddress1 = 0;
  hi2c1.Init.AddressingMode = I2C_ADDRESSINGMODE_7BIT;
  hi2c1.Init.DualAddressMode = I2C_DUALADDRESS_DISABLE;
  hi2c1.Init.OwnAddress2 = 0;
  hi2c1.Init.OwnAddress2Masks = I2C_OA2_NOMASK;
  hi2c1.Init.GeneralCallMode = I2C_GENERALCALL_DISABLE;
  hi2c1.Init.NoStretchMode = I2C_NOSTRETCH_DISABLE;
  if (HAL_I2C_Init(&hi2c1) != HAL_OK)
  {
    Error_Handler();
  }

  /** Configure Analogue filter
  */
  if (HAL_I2CEx_ConfigAnalogFilter(&hi2c1, I2C_ANALOGFILTER_ENABLE) != HAL_OK)
  {
    Error_Handler();
  }

  /** Configure Digital filter
  */
  if (HAL_I2CEx_ConfigDigitalFilter(&hi2c1, 0) != HAL_OK)
  {
    Error_Handler();
  }

}

static void MX_I2C2_Init(void)
{

  hi2c2.Instance = I2C2;
  hi2c2.Init.Timing = 0x107075B0;
  hi2c2.Init.OwnAddress1 = 0;
  hi2c2.Init.AddressingMode = I2C_ADDRESSINGMODE_7BIT;
  hi2c2.Init.DualAddressMode = I2C_DUALADDRESS_DISABLE;
  hi2c2.Init.OwnAddress2 = 0;
  hi2c2.Init.OwnAddress2Masks = I2C_OA2_NOMASK;
  hi2c2.Init.GeneralCallMode = I2C_GENERALCALL_DISABLE;
  hi2c2.Init.NoStretchMode = I2C_NOSTRETCH_DISABLE;
  if (HAL_I2C_Init(&hi2c2) != HAL_OK)
  {
    Error_Handler();
  }

  /** Configure Analogue filter
  */
  if (HAL_I2CEx_ConfigAnalogFilter(&hi2c2, I2C_ANALOGFILTER_ENABLE) != HAL_OK)
  {
    Error_Handler();
  }

  /** Configure Digital filter
  */
  if (HAL_I2CEx_ConfigDigitalFilter(&hi2c2, 0) != HAL_OK)
  {
    Error_Handler();
  }

}

static void MX_I2C4_Init(void)
{

  hi2c4.Instance = I2C4;
  hi2c4.Init.Timing = 0x107075B0;
  hi2c4.Init.OwnAddress1 = 0;
  hi2c4.Init.AddressingMode = I2C_ADDRESSINGMODE_7BIT;
  hi2c4.Init.DualAddressMode = I2C_DUALADDRESS_DISABLE;
  hi2c4.Init.OwnAddress2 = 0;
  hi2c4.Init.OwnAddress2Masks = I2C_OA2_NOMASK;
  hi2c4.Init.GeneralCallMode = I2C_GENERALCALL_DISABLE;
  hi2c4.Init.NoStretchMode = I2C_NOSTRETCH_DISABLE;
  if (HAL_I2C_Init(&hi2c4) != HAL_OK)
  {
    Error_Handler();
  }

  /** Configure Analogue filter
  */
  if (HAL_I2CEx_ConfigAnalogFilter(&hi2c4, I2C_ANALOGFILTER_ENABLE) != HAL_OK)
  {
    Error_Handler();
  }

  /** Configure Digital filter
  */
  if (HAL_I2CEx_ConfigDigitalFilter(&hi2c4, 0) != HAL_OK)
  {
    Error_Handler();
  }

}

static void MX_SPI1_Init(void)
{

  /* SPI1 parameter configuration*/
  hspi1.Instance = SPI1;
  hspi1.Init.Mode = SPI_MODE_MASTER;
  hspi1.Init.Direction = SPI_DIRECTION_2LINES;
  hspi1.Init.DataSize = SPI_DATASIZE_4BIT;
  hspi1.Init.CLKPolarity = SPI_POLARITY_LOW;
  hspi1.Init.CLKPhase = SPI_PHASE_1EDGE;
  hspi1.Init.NSS = SPI_NSS_SOFT;
  hspi1.Init.BaudRatePrescaler = SPI_BAUDRATEPRESCALER_2;
  hspi1.Init.FirstBit = SPI_FIRSTBIT_MSB;
  hspi1.Init.TIMode = SPI_TIMODE_DISABLE;
  hspi1.Init.CRCCalculation = SPI_CRCCALCULATION_DISABLE;
  hspi1.Init.CRCPolynomial = 0x0;
  hspi1.Init.NSSPMode = SPI_NSS_PULSE_ENABLE;
  hspi1.Init.NSSPolarity = SPI_NSS_POLARITY_LOW;
  hspi1.Init.FifoThreshold = SPI_FIFO_THRESHOLD_01DATA;
  hspi1.Init.TxCRCInitializationPattern = SPI_CRC_INITIALIZATION_ALL_ZERO_PATTERN;
  hspi1.Init.RxCRCInitializationPattern = SPI_CRC_INITIALIZATION_ALL_ZERO_PATTERN;
  hspi1.Init.MasterSSIdleness = SPI_MASTER_SS_IDLENESS_00CYCLE;
  hspi1.Init.MasterInterDataIdleness = SPI_MASTER_INTERDATA_IDLENESS_00CYCLE;
  hspi1.Init.MasterReceiverAutoSusp = SPI_MASTER_RX_AUTOSUSP_DISABLE;
  hspi1.Init.MasterKeepIOState = SPI_MASTER_KEEP_IO_STATE_DISABLE;
  hspi1.Init.IOSwap = SPI_IO_SWAP_DISABLE;
  if (HAL_SPI_Init(&hspi1) != HAL_OK)
  {
    Error_Handler();
  }

}

static void MX_SPI3_Init(void)
{

  /* SPI3 parameter configuration*/
  hspi3.Instance = SPI3;
  hspi3.Init.Mode = SPI_MODE_MASTER;
  hspi3.Init.Direction = SPI_DIRECTION_2LINES;
  hspi3.Init.DataSize = SPI_DATASIZE_8BIT;
  hspi3.Init.CLKPolarity = SPI_POLARITY_LOW;
  hspi3.Init.CLKPhase = SPI_PHASE_1EDGE;
  hspi3.Init.NSS = SPI_NSS_SOFT;
  hspi3.Init.BaudRatePrescaler = SPI_BAUDRATEPRESCALER_32;
  hspi3.Init.FirstBit = SPI_FIRSTBIT_MSB;
  hspi3.Init.TIMode = SPI_TIMODE_DISABLE;
  hspi3.Init.CRCCalculation = SPI_CRCCALCULATION_DISABLE;
  hspi3.Init.CRCPolynomial = 0x0;
  hspi3.Init.NSSPMode = SPI_NSS_PULSE_ENABLE;
  hspi3.Init.NSSPolarity = SPI_NSS_POLARITY_LOW;
  hspi3.Init.FifoThreshold = SPI_FIFO_THRESHOLD_01DATA;
  hspi3.Init.TxCRCInitializationPattern = SPI_CRC_INITIALIZATION_ALL_ZERO_PATTERN;
  hspi3.Init.RxCRCInitializationPattern = SPI_CRC_INITIALIZATION_ALL_ZERO_PATTERN;
  hspi3.Init.MasterSSIdleness = SPI_MASTER_SS_IDLENESS_00CYCLE;
  hspi3.Init.MasterInterDataIdleness = SPI_MASTER_INTERDATA_IDLENESS_00CYCLE;
  hspi3.Init.MasterReceiverAutoSusp = SPI_MASTER_RX_AUTOSUSP_DISABLE;
  hspi3.Init.MasterKeepIOState = SPI_MASTER_KEEP_IO_STATE_DISABLE;
  hspi3.Init.IOSwap = SPI_IO_SWAP_DISABLE;
  if (HAL_SPI_Init(&hspi3) != HAL_OK)
  {
    Error_Handler();
  }

}

static void MX_SPI4_Init(void)
{

  /* SPI4 parameter configuration*/
  hspi4.Instance = SPI4;
  hspi4.Init.Mode = SPI_MODE_MASTER;
  hspi4.Init.Direction = SPI_DIRECTION_2LINES;
  hspi4.Init.DataSize = SPI_DATASIZE_4BIT;
  hspi4.Init.CLKPolarity = SPI_POLARITY_LOW;
  hspi4.Init.CLKPhase = SPI_PHASE_1EDGE;
  hspi4.Init.NSS = SPI_NSS_SOFT;
  hspi4.Init.BaudRatePrescaler = SPI_BAUDRATEPRESCALER_2;
  hspi4.Init.FirstBit = SPI_FIRSTBIT_MSB;
  hspi4.Init.TIMode = SPI_TIMODE_DISABLE;
  hspi4.Init.CRCCalculation = SPI_CRCCALCULATION_DISABLE;
  hspi4.Init.CRCPolynomial = 0x0;
  hspi4.Init.NSSPMode = SPI_NSS_PULSE_ENABLE;
  hspi4.Init.NSSPolarity = SPI_NSS_POLARITY_LOW;
  hspi4.Init.FifoThreshold = SPI_FIFO_THRESHOLD_01DATA;
  hspi4.Init.TxCRCInitializationPattern = SPI_CRC_INITIALIZATION_ALL_ZERO_PATTERN;
  hspi4.Init.RxCRCInitializationPattern = SPI_CRC_INITIALIZATION_ALL_ZERO_PATTERN;
  hspi4.Init.MasterSSIdleness = SPI_MASTER_SS_IDLENESS_00CYCLE;
  hspi4.Init.MasterInterDataIdleness = SPI_MASTER_INTERDATA_IDLENESS_00CYCLE;
  hspi4.Init.MasterReceiverAutoSusp = SPI_MASTER_RX_AUTOSUSP_DISABLE;
  hspi4.Init.MasterKeepIOState = SPI_MASTER_KEEP_IO_STATE_DISABLE;
  hspi4.Init.IOSwap = SPI_IO_SWAP_DISABLE;
  if (HAL_SPI_Init(&hspi4) != HAL_OK)
  {
    Error_Handler();
  }

}

static void MX_SPI6_Init(void)
{

  /* SPI6 parameter configuration*/
  hspi6.Instance = SPI6;
  hspi6.Init.Mode = SPI_MODE_MASTER;
  hspi6.Init.Direction = SPI_DIRECTION_2LINES;
  hspi6.Init.DataSize = SPI_DATASIZE_8BIT;
  hspi6.Init.CLKPolarity = SPI_POLARITY_HIGH;
  hspi6.Init.CLKPhase = SPI_PHASE_2EDGE;
  hspi6.Init.NSS = SPI_NSS_SOFT;
  hspi6.Init.BaudRatePrescaler = SPI_BAUDRATEPRESCALER_64;
  hspi6.Init.FirstBit = SPI_FIRSTBIT_MSB;
  hspi6.Init.TIMode = SPI_TIMODE_DISABLE;
  hspi6.Init.CRCCalculation = SPI_CRCCALCULATION_DISABLE;
  hspi6.Init.CRCPolynomial = 0x0;
  hspi6.Init.NSSPMode = SPI_NSS_PULSE_ENABLE;
  hspi6.Init.NSSPolarity = SPI_NSS_POLARITY_LOW;
  hspi6.Init.FifoThreshold = SPI_FIFO_THRESHOLD_01DATA;
  hspi6.Init.TxCRCInitializationPattern = SPI_CRC_INITIALIZATION_ALL_ZERO_PATTERN;
  hspi6.Init.RxCRCInitializationPattern = SPI_CRC_INITIALIZATION_ALL_ZERO_PATTERN;
  hspi6.Init.MasterSSIdleness = SPI_MASTER_SS_IDLENESS_00CYCLE;
  hspi6.Init.MasterInterDataIdleness = SPI_MASTER_INTERDATA_IDLENESS_00CYCLE;
  hspi6.Init.MasterReceiverAutoSusp = SPI_MASTER_RX_AUTOSUSP_DISABLE;
  hspi6.Init.MasterKeepIOState = SPI_MASTER_KEEP_IO_STATE_DISABLE;
  hspi6.Init.IOSwap = SPI_IO_SWAP_DISABLE;
  if (HAL_SPI_Init(&hspi6) != HAL_OK)
  {
    Error_Handler();
  }

}

static void MX_TIM1_Init(void)
{

  TIM_ClockConfigTypeDef sClockSourceConfig = {0};
  TIM_MasterConfigTypeDef sMasterConfig = {0};
  TIM_OC_InitTypeDef sConfigOC = {0};
  TIM_BreakDeadTimeConfigTypeDef sBreakDeadTimeConfig = {0};

  htim1.Instance = TIM1;
  htim1.Init.Prescaler = 0;
  htim1.Init.CounterMode = TIM_COUNTERMODE_UP;
  htim1.Init.Period = 199;
  htim1.Init.ClockDivision = TIM_CLOCKDIVISION_DIV1;
  htim1.Init.RepetitionCounter = 0;
  htim1.Init.AutoReloadPreload = TIM_AUTORELOAD_PRELOAD_DISABLE;
  if (HAL_TIM_Base_Init(&htim1) != HAL_OK)
  {
    Error_Handler();
  }
  sClockSourceConfig.ClockSource = TIM_CLOCKSOURCE_INTERNAL;
  if (HAL_TIM_ConfigClockSource(&htim1, &sClockSourceConfig) != HAL_OK)
  {
    Error_Handler();
  }
  if (HAL_TIM_PWM_Init(&htim1) != HAL_OK)
  {
    Error_Handler();
  }
  sMasterConfig.MasterOutputTrigger = TIM_TRGO_RESET;
  sMasterConfig.MasterOutputTrigger2 = TIM_TRGO2_RESET;
  sMasterConfig.MasterSlaveMode = TIM_MASTERSLAVEMODE_DISABLE;
  if (HAL_TIMEx_MasterConfigSynchronization(&htim1, &sMasterConfig) != HAL_OK)
  {
    Error_Handler();
  }
  sConfigOC.OCMode = TIM_OCMODE_PWM1;
  sConfigOC.Pulse = 0;
  sConfigOC.OCPolarity = TIM_OCPOLARITY_HIGH;
  sConfigOC.OCNPolarity = TIM_OCNPOLARITY_HIGH;
  sConfigOC.OCFastMode = TIM_OCFAST_DISABLE;
  sConfigOC.OCIdleState = TIM_OCIDLESTATE_RESET;
  sConfigOC.OCNIdleState = TIM_OCNIDLESTATE_RESET;
  if (HAL_TIM_PWM_ConfigChannel(&htim1, &sConfigOC, TIM_CHANNEL_1) != HAL_OK)
  {
    Error_Handler();
  }
  if (HAL_TIM_PWM_ConfigChannel(&htim1, &sConfigOC, TIM_CHANNEL_2) != HAL_OK)
  {
    Error_Handler();
  }
  if (HAL_TIM_PWM_ConfigChannel(&htim1, &sConfigOC, TIM_CHANNEL_3) != HAL_OK)
  {
    Error_Handler();
  }
  if (HAL_TIM_PWM_ConfigChannel(&htim1, &sConfigOC, TIM_CHANNEL_4) != HAL_OK)
  {
    Error_Handler();
  }
  sBreakDeadTimeConfig.OffStateRunMode = TIM_OSSR_DISABLE;
  sBreakDeadTimeConfig.OffStateIDLEMode = TIM_OSSI_DISABLE;
  sBreakDeadTimeConfig.LockLevel = TIM_LOCKLEVEL_OFF;
  sBreakDeadTimeConfig.DeadTime = 0;
  sBreakDeadTimeConfig.BreakState = TIM_BREAK_DISABLE;
  sBreakDeadTimeConfig.BreakPolarity = TIM_BREAKPOLARITY_HIGH;
  sBreakDeadTimeConfig.BreakFilter = 0;
  sBreakDeadTimeConfig.Break2State = TIM_BREAK2_DISABLE;
  sBreakDeadTimeConfig.Break2Polarity = TIM_BREAK2POLARITY_HIGH;
  sBreakDeadTimeConfig.Break2Filter = 0;
  sBreakDeadTimeConfig.AutomaticOutput = TIM_AUTOMATICOUTPUT_DISABLE;
  if (HAL_TIMEx_ConfigBreakDeadTime(&htim1, &sBreakDeadTimeConfig) != HAL_OK)
  {
    Error_Handler();
  }
  HAL_TIM_MspPostInit(&htim1);

}

static void MX_TIM2_Init(void)
{

  TIM_ClockConfigTypeDef sClockSourceConfig = {0};
  TIM_MasterConfigTypeDef sMasterConfig = {0};

  htim2.Instance = TIM2;
  htim2.Init.Prescaler = 0;
  htim2.Init.CounterMode = TIM_COUNTERMODE_UP;
  htim2.Init.Period = 4294967295;
  htim2.Init.ClockDivision = TIM_CLOCKDIVISION_DIV1;
  htim2.Init.AutoReloadPreload = TIM_AUTORELOAD_PRELOAD_DISABLE;
  if (HAL_TIM_Base_Init(&htim2) != HAL_OK)
  {
    Error_Handler();
  }
  sClockSourceConfig.ClockSource = TIM_CLOCKSOURCE_INTERNAL;
  if (HAL_TIM_ConfigClockSource(&htim2, &sClockSourceConfig) != HAL_OK)
  {
    Error_Handler();
  }
  sMasterConfig.MasterOutputTrigger = TIM_TRGO_RESET;
  sMasterConfig.MasterSlaveMode = TIM_MASTERSLAVEMODE_DISABLE;
  if (HAL_TIMEx_MasterConfigSynchronization(&htim2, &sMasterConfig) != HAL_OK)
  {
    Error_Handler();
  }

}

static void MX_TIM3_Init(void)
{

  TIM_ClockConfigTypeDef sClockSourceConfig = {0};
  TIM_MasterConfigTypeDef sMasterConfig = {0};

  htim3.Instance = TIM3;
  htim3.Init.Prescaler = 0;
  htim3.Init.CounterMode = TIM_COUNTERMODE_UP;
  htim3.Init.Period = 65535;
  htim3.Init.ClockDivision = TIM_CLOCKDIVISION_DIV1;
  htim3.Init.AutoReloadPreload = TIM_AUTORELOAD_PRELOAD_DISABLE;
  if (HAL_TIM_Base_Init(&htim3) != HAL_OK)
  {
    Error_Handler();
  }
  sClockSourceConfig.ClockSource = TIM_CLOCKSOURCE_INTERNAL;
  if (HAL_TIM_ConfigClockSource(&htim3, &sClockSourceConfig) != HAL_OK)
  {
    Error_Handler();
  }
  sMasterConfig.MasterOutputTrigger = TIM_TRGO_RESET;
  sMasterConfig.MasterSlaveMode = TIM_MASTERSLAVEMODE_DISABLE;
  if (HAL_TIMEx_MasterConfigSynchronization(&htim3, &sMasterConfig) != HAL_OK)
  {
    Error_Handler();
  }

}

static void MX_TIM4_Init(void)
{

  TIM_ClockConfigTypeDef sClockSourceConfig = {0};
  TIM_MasterConfigTypeDef sMasterConfig = {0};
  TIM_OC_InitTypeDef sConfigOC = {0};

  htim4.Instance = TIM4;
  htim4.Init.Prescaler = 0;
  htim4.Init.CounterMode = TIM_COUNTERMODE_UP;
  htim4.Init.Period = 65535;
  htim4.Init.ClockDivision = TIM_CLOCKDIVISION_DIV1;
  htim4.Init.AutoReloadPreload = TIM_AUTORELOAD_PRELOAD_DISABLE;
  if (HAL_TIM_Base_Init(&htim4) != HAL_OK)
  {
    Error_Handler();
  }
  sClockSourceConfig.ClockSource = TIM_CLOCKSOURCE_INTERNAL;
  if (HAL_TIM_ConfigClockSource(&htim4, &sClockSourceConfig) != HAL_OK)
  {
    Error_Handler();
  }
  if (HAL_TIM_PWM_Init(&htim4) != HAL_OK)
  {
    Error_Handler();
  }
  sMasterConfig.MasterOutputTrigger = TIM_TRGO_RESET;
  sMasterConfig.MasterSlaveMode = TIM_MASTERSLAVEMODE_DISABLE;
  if (HAL_TIMEx_MasterConfigSynchronization(&htim4, &sMasterConfig) != HAL_OK)
  {
    Error_Handler();
  }
  sConfigOC.OCMode = TIM_OCMODE_PWM1;
  sConfigOC.Pulse = 0;
  sConfigOC.OCPolarity = TIM_OCPOLARITY_HIGH;
  sConfigOC.OCFastMode = TIM_OCFAST_DISABLE;
  if (HAL_TIM_PWM_ConfigChannel(&htim4, &sConfigOC, TIM_CHANNEL_1) != HAL_OK)
  {
    Error_Handler();
  }
  if (HAL_TIM_PWM_ConfigChannel(&htim4, &sConfigOC, TIM_CHANNEL_2) != HAL_OK)
  {
    Error_Handler();
  }
  if (HAL_TIM_PWM_ConfigChannel(&htim4, &sConfigOC, TIM_CHANNEL_3) != HAL_OK)
  {
    Error_Handler();
  }
  if (HAL_TIM_PWM_ConfigChannel(&htim4, &sConfigOC, TIM_CHANNEL_4) != HAL_OK)
  {
    Error_Handler();
  }
  HAL_TIM_MspPostInit(&htim4);

}

static void MX_TIM5_Init(void)
{

  TIM_ClockConfigTypeDef sClockSourceConfig = {0};
  TIM_MasterConfigTypeDef sMasterConfig = {0};

  htim5.Instance = TIM5;
  htim5.Init.Prescaler = 0;
  htim5.Init.CounterMode = TIM_COUNTERMODE_UP;
  htim5.Init.Period = 4294967295;
  htim5.Init.ClockDivision = TIM_CLOCKDIVISION_DIV1;
  htim5.Init.AutoReloadPreload = TIM_AUTORELOAD_PRELOAD_DISABLE;
  if (HAL_TIM_Base_Init(&htim5) != HAL_OK)
  {
    Error_Handler();
  }
  sClockSourceConfig.ClockSource = TIM_CLOCKSOURCE_INTERNAL;
  if (HAL_TIM_ConfigClockSource(&htim5, &sClockSourceConfig) != HAL_OK)
  {
    Error_Handler();
  }
  sMasterConfig.MasterOutputTrigger = TIM_TRGO_RESET;
  sMasterConfig.MasterSlaveMode = TIM_MASTERSLAVEMODE_DISABLE;
  if (HAL_TIMEx_MasterConfigSynchronization(&htim5, &sMasterConfig) != HAL_OK)
  {
    Error_Handler();
  }

}

static void MX_TIM8_Init(void)
{

  TIM_MasterConfigTypeDef sMasterConfig = {0};
  TIM_OC_InitTypeDef sConfigOC = {0};
  TIM_BreakDeadTimeConfigTypeDef sBreakDeadTimeConfig = {0};

  htim8.Instance = TIM8;
  htim8.Init.Prescaler = 0;
  htim8.Init.CounterMode = TIM_COUNTERMODE_UP;
  htim8.Init.Period = 65535;
  htim8.Init.ClockDivision = TIM_CLOCKDIVISION_DIV1;
  htim8.Init.RepetitionCounter = 0;
  htim8.Init.AutoReloadPreload = TIM_AUTORELOAD_PRELOAD_DISABLE;
  if (HAL_TIM_PWM_Init(&htim8) != HAL_OK)
  {
    Error_Handler();
  }
  if (HAL_TIM_OC_Init(&htim8) != HAL_OK)
  {
    Error_Handler();
  }
  sMasterConfig.MasterOutputTrigger = TIM_TRGO_RESET;
  sMasterConfig.MasterOutputTrigger2 = TIM_TRGO2_RESET;
  sMasterConfig.MasterSlaveMode = TIM_MASTERSLAVEMODE_DISABLE;
  if (HAL_TIMEx_MasterConfigSynchronization(&htim8, &sMasterConfig) != HAL_OK)
  {
    Error_Handler();
  }
  sConfigOC.OCMode = TIM_OCMODE_PWM1;
  sConfigOC.Pulse = 0;
  sConfigOC.OCPolarity = TIM_OCPOLARITY_HIGH;
  sConfigOC.OCNPolarity = TIM_OCNPOLARITY_HIGH;
  sConfigOC.OCFastMode = TIM_OCFAST_DISABLE;
  sConfigOC.OCIdleState = TIM_OCIDLESTATE_RESET;
  sConfigOC.OCNIdleState = TIM_OCNIDLESTATE_RESET;
  if (HAL_TIM_PWM_ConfigChannel(&htim8, &sConfigOC, TIM_CHANNEL_1) != HAL_OK)
  {
    Error_Handler();
  }
  if (HAL_TIM_PWM_ConfigChannel(&htim8, &sConfigOC, TIM_CHANNEL_2) != HAL_OK)
  {
    Error_Handler();
  }
  if (HAL_TIM_PWM_ConfigChannel(&htim8, &sConfigOC, TIM_CHANNEL_3) != HAL_OK)
  {
    Error_Handler();
  }
  sConfigOC.OCMode = TIM_OCMODE_TIMING;
  if (HAL_TIM_OC_ConfigChannel(&htim8, &sConfigOC, TIM_CHANNEL_4) != HAL_OK)
  {
    Error_Handler();
  }
  sBreakDeadTimeConfig.OffStateRunMode = TIM_OSSR_DISABLE;
  sBreakDeadTimeConfig.OffStateIDLEMode = TIM_OSSI_DISABLE;
  sBreakDeadTimeConfig.LockLevel = TIM_LOCKLEVEL_OFF;
  sBreakDeadTimeConfig.DeadTime = 0;
  sBreakDeadTimeConfig.BreakState = TIM_BREAK_DISABLE;
  sBreakDeadTimeConfig.BreakPolarity = TIM_BREAKPOLARITY_HIGH;
  sBreakDeadTimeConfig.BreakFilter = 0;
  sBreakDeadTimeConfig.Break2State = TIM_BREAK2_DISABLE;
  sBreakDeadTimeConfig.Break2Polarity = TIM_BREAK2POLARITY_HIGH;
  sBreakDeadTimeConfig.Break2Filter = 0;
  sBreakDeadTimeConfig.AutomaticOutput = TIM_AUTOMATICOUTPUT_DISABLE;
  if (HAL_TIMEx_ConfigBreakDeadTime(&htim8, &sBreakDeadTimeConfig) != HAL_OK)
  {
    Error_Handler();
  }
  HAL_TIM_MspPostInit(&htim8);

}

static void MX_UART4_Init(void)
{

  huart4.Instance = UART4;
  huart4.Init.BaudRate = 100000;
  huart4.Init.WordLength = UART_WORDLENGTH_9B;
  huart4.Init.StopBits = UART_STOPBITS_2;
  huart4.Init.Parity = UART_PARITY_EVEN;
  huart4.Init.Mode = UART_MODE_TX_RX;
  huart4.Init.HwFlowCtl = UART_HWCONTROL_NONE;
  huart4.Init.OverSampling = UART_OVERSAMPLING_16;
  huart4.Init.OneBitSampling = UART_ONE_BIT_SAMPLE_DISABLE;
  huart4.Init.ClockPrescaler = UART_PRESCALER_DIV1;
  huart4.AdvancedInit.AdvFeatureInit = UART_ADVFEATURE_RXINVERT_INIT;
  huart4.AdvancedInit.RxPinLevelInvert = UART_ADVFEATURE_RXINV_ENABLE;
  if (HAL_UART_Init(&huart4) != HAL_OK)
  {
    Error_Handler();
  }
  if (HAL_UARTEx_SetTxFifoThreshold(&huart4, UART_TXFIFO_THRESHOLD_1_8) != HAL_OK)
  {
    Error_Handler();
  }
  if (HAL_UARTEx_SetRxFifoThreshold(&huart4, UART_RXFIFO_THRESHOLD_1_8) != HAL_OK)
  {
    Error_Handler();
  }
  if (HAL_UARTEx_DisableFifoMode(&huart4) != HAL_OK)
  {
    Error_Handler();
  }

}

static void MX_UART5_Init(void)
{

  huart5.Instance = UART5;
  huart5.Init.BaudRate = 115200;
  huart5.Init.WordLength = UART_WORDLENGTH_8B;
  huart5.Init.StopBits = UART_STOPBITS_1;
  huart5.Init.Parity = UART_PARITY_NONE;
  huart5.Init.Mode = UART_MODE_TX_RX;
  huart5.Init.HwFlowCtl = UART_HWCONTROL_NONE;
  huart5.Init.OverSampling = UART_OVERSAMPLING_16;
  huart5.Init.OneBitSampling = UART_ONE_BIT_SAMPLE_DISABLE;
  huart5.Init.ClockPrescaler = UART_PRESCALER_DIV1;
  huart5.AdvancedInit.AdvFeatureInit = UART_ADVFEATURE_NO_INIT;
  if (HAL_UART_Init(&huart5) != HAL_OK)
  {
    Error_Handler();
  }
  if (HAL_UARTEx_SetTxFifoThreshold(&huart5, UART_TXFIFO_THRESHOLD_1_8) != HAL_OK)
  {
    Error_Handler();
  }
  if (HAL_UARTEx_SetRxFifoThreshold(&huart5, UART_RXFIFO_THRESHOLD_1_8) != HAL_OK)
  {
    Error_Handler();
  }
  if (HAL_UARTEx_DisableFifoMode(&huart5) != HAL_OK)
  {
    Error_Handler();
  }

}

static void MX_UART7_Init(void)
{

  huart7.Instance = UART7;
  huart7.Init.BaudRate = 115200;
  huart7.Init.WordLength = UART_WORDLENGTH_8B;
  huart7.Init.StopBits = UART_STOPBITS_1;
  huart7.Init.Parity = UART_PARITY_NONE;
  huart7.Init.Mode = UART_MODE_TX_RX;
  huart7.Init.HwFlowCtl = UART_HWCONTROL_NONE;
  huart7.Init.OverSampling = UART_OVERSAMPLING_16;
  huart7.Init.OneBitSampling = UART_ONE_BIT_SAMPLE_DISABLE;
  huart7.Init.ClockPrescaler = UART_PRESCALER_DIV1;
  huart7.AdvancedInit.AdvFeatureInit = UART_ADVFEATURE_NO_INIT;
  if (HAL_UART_Init(&huart7) != HAL_OK)
  {
    Error_Handler();
  }
  if (HAL_UARTEx_SetTxFifoThreshold(&huart7, UART_TXFIFO_THRESHOLD_1_8) != HAL_OK)
  {
    Error_Handler();
  }
  if (HAL_UARTEx_SetRxFifoThreshold(&huart7, UART_RXFIFO_THRESHOLD_1_8) != HAL_OK)
  {
    Error_Handler();
  }
  if (HAL_UARTEx_DisableFifoMode(&huart7) != HAL_OK)
  {
    Error_Handler();
  }

}

static void MX_UART8_Init(void)
{

  huart8.Instance = UART8;
  huart8.Init.BaudRate = 420000;
  huart8.Init.WordLength = UART_WORDLENGTH_8B;
  huart8.Init.StopBits = UART_STOPBITS_1;
  huart8.Init.Parity = UART_PARITY_NONE;
  huart8.Init.Mode = UART_MODE_TX_RX;
  huart8.Init.HwFlowCtl = UART_HWCONTROL_NONE;
  huart8.Init.OverSampling = UART_OVERSAMPLING_8;
  huart8.Init.OneBitSampling = UART_ONE_BIT_SAMPLE_DISABLE;
  huart8.Init.ClockPrescaler = UART_PRESCALER_DIV1;
  huart8.AdvancedInit.AdvFeatureInit = UART_ADVFEATURE_DMADISABLEONERROR_INIT;
  huart8.AdvancedInit.DMADisableonRxError = UART_ADVFEATURE_DMA_DISABLEONRXERROR;
  if (HAL_UART_Init(&huart8) != HAL_OK)
  {
    Error_Handler();
  }
  if (HAL_UARTEx_SetTxFifoThreshold(&huart8, UART_TXFIFO_THRESHOLD_1_8) != HAL_OK)
  {
    Error_Handler();
  }
  if (HAL_UARTEx_SetRxFifoThreshold(&huart8, UART_RXFIFO_THRESHOLD_1_8) != HAL_OK)
  {
    Error_Handler();
  }
  if (HAL_UARTEx_DisableFifoMode(&huart8) != HAL_OK)
  {
    Error_Handler();
  }

}

static void MX_USART1_UART_Init(void)
{

  huart1.Instance = USART1;
  huart1.Init.BaudRate = 115200;
  huart1.Init.WordLength = UART_WORDLENGTH_8B;
  huart1.Init.StopBits = UART_STOPBITS_1;
  huart1.Init.Parity = UART_PARITY_NONE;
  huart1.Init.Mode = UART_MODE_TX_RX;
  huart1.Init.HwFlowCtl = UART_HWCONTROL_NONE;
  huart1.Init.OverSampling = UART_OVERSAMPLING_16;
  huart1.Init.OneBitSampling = UART_ONE_BIT_SAMPLE_DISABLE;
  huart1.Init.ClockPrescaler = UART_PRESCALER_DIV1;
  huart1.AdvancedInit.AdvFeatureInit = UART_ADVFEATURE_NO_INIT;
  if (HAL_UART_Init(&huart1) != HAL_OK)
  {
    Error_Handler();
  }
  if (HAL_UARTEx_SetTxFifoThreshold(&huart1, UART_TXFIFO_THRESHOLD_1_8) != HAL_OK)
  {
    Error_Handler();
  }
  if (HAL_UARTEx_SetRxFifoThreshold(&huart1, UART_RXFIFO_THRESHOLD_1_8) != HAL_OK)
  {
    Error_Handler();
  }
  if (HAL_UARTEx_DisableFifoMode(&huart1) != HAL_OK)
  {
    Error_Handler();
  }

}

static void MX_USART2_UART_Init(void)
{

  huart2.Instance = USART2;
  huart2.Init.BaudRate = 115200;
  huart2.Init.WordLength = UART_WORDLENGTH_8B;
  huart2.Init.StopBits = UART_STOPBITS_1;
  huart2.Init.Parity = UART_PARITY_NONE;
  huart2.Init.Mode = UART_MODE_TX_RX;
  huart2.Init.HwFlowCtl = UART_HWCONTROL_NONE;
  huart2.Init.OverSampling = UART_OVERSAMPLING_16;
  huart2.Init.OneBitSampling = UART_ONE_BIT_SAMPLE_DISABLE;
  huart2.Init.ClockPrescaler = UART_PRESCALER_DIV1;
  huart2.AdvancedInit.AdvFeatureInit = UART_ADVFEATURE_NO_INIT;
  if (HAL_UART_Init(&huart2) != HAL_OK)
  {
    Error_Handler();
  }
  if (HAL_UARTEx_SetTxFifoThreshold(&huart2, UART_TXFIFO_THRESHOLD_1_8) != HAL_OK)
  {
    Error_Handler();
  }
  if (HAL_UARTEx_SetRxFifoThreshold(&huart2, UART_RXFIFO_THRESHOLD_1_8) != HAL_OK)
  {
    Error_Handler();
  }
  if (HAL_UARTEx_DisableFifoMode(&huart2) != HAL_OK)
  {
    Error_Handler();
  }

}

static void MX_USART3_UART_Init(void)
{

  huart3.Instance = USART3;
  huart3.Init.BaudRate = 115200;
  huart3.Init.WordLength = UART_WORDLENGTH_8B;
  huart3.Init.StopBits = UART_STOPBITS_1;
  huart3.Init.Parity = UART_PARITY_NONE;
  huart3.Init.Mode = UART_MODE_TX_RX;
  huart3.Init.HwFlowCtl = UART_HWCONTROL_NONE;
  huart3.Init.OverSampling = UART_OVERSAMPLING_16;
  huart3.Init.OneBitSampling = UART_ONE_BIT_SAMPLE_DISABLE;
  huart3.Init.ClockPrescaler = UART_PRESCALER_DIV1;
  huart3.AdvancedInit.AdvFeatureInit = UART_ADVFEATURE_NO_INIT;
  if (HAL_UART_Init(&huart3) != HAL_OK)
  {
    Error_Handler();
  }
  if (HAL_UARTEx_SetTxFifoThreshold(&huart3, UART_TXFIFO_THRESHOLD_1_8) != HAL_OK)
  {
    Error_Handler();
  }
  if (HAL_UARTEx_SetRxFifoThreshold(&huart3, UART_RXFIFO_THRESHOLD_1_8) != HAL_OK)
  {
    Error_Handler();
  }
  if (HAL_UARTEx_DisableFifoMode(&huart3) != HAL_OK)
  {
    Error_Handler();
  }

}

static void MX_DMA_Init(void)
{

  /* DMA controller clock enable */
  __HAL_RCC_DMA1_CLK_ENABLE();

  /* DMA interrupt init */
  /* DMA1_Stream0_IRQn interrupt configuration */
  HAL_NVIC_SetPriority(DMA1_Stream0_IRQn, 0, 0);
  HAL_NVIC_EnableIRQ(DMA1_Stream0_IRQn);
  /* DMA1_Stream1_IRQn interrupt configuration */
  HAL_NVIC_SetPriority(DMA1_Stream1_IRQn, 0, 0);
  HAL_NVIC_EnableIRQ(DMA1_Stream1_IRQn);
  /* DMA1_Stream2_IRQn interrupt configuration */
  HAL_NVIC_SetPriority(DMA1_Stream2_IRQn, 0, 0);
  HAL_NVIC_EnableIRQ(DMA1_Stream2_IRQn);
  /* DMA1_Stream3_IRQn interrupt configuration */
  HAL_NVIC_SetPriority(DMA1_Stream3_IRQn, 0, 0);
  HAL_NVIC_EnableIRQ(DMA1_Stream3_IRQn);
  /* DMA1_Stream4_IRQn interrupt configuration */
  HAL_NVIC_SetPriority(DMA1_Stream4_IRQn, 0, 0);
  HAL_NVIC_EnableIRQ(DMA1_Stream4_IRQn);
  /* DMA1_Stream5_IRQn interrupt configuration */
  HAL_NVIC_SetPriority(DMA1_Stream5_IRQn, 0, 0);
  HAL_NVIC_EnableIRQ(DMA1_Stream5_IRQn);

}

static void MX_GPIO_Init(void)
{
  GPIO_InitTypeDef GPIO_InitStruct = {0};

  /* GPIO Ports Clock Enable */
  __HAL_RCC_GPIOE_CLK_ENABLE();
  __HAL_RCC_GPIOC_CLK_ENABLE();
  __HAL_RCC_GPIOH_CLK_ENABLE();
  __HAL_RCC_GPIOA_CLK_ENABLE();
  __HAL_RCC_GPIOB_CLK_ENABLE();
  __HAL_RCC_GPIOD_CLK_ENABLE();

  /*Configure GPIO pin Output Level */
  HAL_GPIO_WritePin(OSD_CS_GPIO_Port, OSD_CS_Pin, GPIO_PIN_RESET);

  /*Configure GPIO pin Output Level */
  HAL_GPIO_WritePin(FLASH_CS_GPIO_Port, FLASH_CS_Pin, GPIO_PIN_RESET);

  /*Configure GPIO pin Output Level */
  HAL_GPIO_WritePin(STATUS_LED_2_GPIO_Port, STATUS_LED_2_Pin, GPIO_PIN_SET);

  /*Configure GPIO pin Output Level */
  HAL_GPIO_WritePin(STATUS_LED_1_GPIO_Port, STATUS_LED_1_Pin, GPIO_PIN_SET);

  /*Configure GPIO pin Output Level */
  HAL_GPIO_WritePin(GPIOD, IMU_CS_Pin|IMU2_CS_Pin, GPIO_PIN_RESET);

  /*Configure GPIO pin : IMU2_INT_Pin */
  GPIO_InitStruct.Pin = IMU2_INT_Pin;
  GPIO_InitStruct.Mode = GPIO_MODE_IT_RISING;
  GPIO_InitStruct.Pull = GPIO_NOPULL;
  HAL_GPIO_Init(IMU2_INT_GPIO_Port, &GPIO_InitStruct);

  /*Configure GPIO pins : OSD_CS_Pin STATUS_LED_2_Pin */
  GPIO_InitStruct.Pin = OSD_CS_Pin|STATUS_LED_2_Pin;
  GPIO_InitStruct.Mode = GPIO_MODE_OUTPUT_PP;
  GPIO_InitStruct.Pull = GPIO_NOPULL;
  GPIO_InitStruct.Speed = GPIO_SPEED_FREQ_LOW;
  HAL_GPIO_Init(GPIOC, &GPIO_InitStruct);

  /*Configure GPIO pin : FLASH_CS_Pin */
  GPIO_InitStruct.Pin = FLASH_CS_Pin;
  GPIO_InitStruct.Mode = GPIO_MODE_OUTPUT_PP;
  GPIO_InitStruct.Pull = GPIO_NOPULL;
  GPIO_InitStruct.Speed = GPIO_SPEED_FREQ_LOW;
  HAL_GPIO_Init(FLASH_CS_GPIO_Port, &GPIO_InitStruct);

  /*Configure GPIO pin : STATUS_LED_1_Pin */
  GPIO_InitStruct.Pin = STATUS_LED_1_Pin;
  GPIO_InitStruct.Mode = GPIO_MODE_OUTPUT_PP;
  GPIO_InitStruct.Pull = GPIO_NOPULL;
  GPIO_InitStruct.Speed = GPIO_SPEED_FREQ_LOW;
  HAL_GPIO_Init(STATUS_LED_1_GPIO_Port, &GPIO_InitStruct);

  /*Configure GPIO pin : BMP_INT1_Pin */
  GPIO_InitStruct.Pin = BMP_INT1_Pin;
  GPIO_InitStruct.Mode = GPIO_MODE_IT_RISING;
  GPIO_InitStruct.Pull = GPIO_NOPULL;
  HAL_GPIO_Init(BMP_INT1_GPIO_Port, &GPIO_InitStruct);

  /*Configure GPIO pin : IMU_INT1_Pin */
  GPIO_InitStruct.Pin = IMU_INT1_Pin;
  GPIO_InitStruct.Mode = GPIO_MODE_IT_RISING;
  GPIO_InitStruct.Pull = GPIO_NOPULL;
  HAL_GPIO_Init(IMU_INT1_GPIO_Port, &GPIO_InitStruct);

  /*Configure GPIO pins : IMU_CS_Pin IMU2_CS_Pin */
  GPIO_InitStruct.Pin = IMU_CS_Pin|IMU2_CS_Pin;
  GPIO_InitStruct.Mode = GPIO_MODE_OUTPUT_PP;
  GPIO_InitStruct.Pull = GPIO_NOPULL;
  GPIO_InitStruct.Speed = GPIO_SPEED_FREQ_LOW;
  HAL_GPIO_Init(GPIOD, &GPIO_InitStruct);

}

 /* MPU Configuration */

void MPU_Config(void)
{
  MPU_Region_InitTypeDef MPU_InitStruct = {0};

  /* Disables the MPU */
  HAL_MPU_Disable();

  /** Initializes and configures the Region and the memory to be protected
  */
  MPU_InitStruct.Enable = MPU_REGION_ENABLE;
  MPU_InitStruct.Number = MPU_REGION_NUMBER0;
  MPU_InitStruct.BaseAddress = 0x0;
  MPU_InitStruct.Size = MPU_REGION_SIZE_4GB;
  MPU_InitStruct.SubRegionDisable = 0x87;
  MPU_InitStruct.TypeExtField = MPU_TEX_LEVEL0;
  MPU_InitStruct.AccessPermission = MPU_REGION_NO_ACCESS;
  MPU_InitStruct.DisableExec = MPU_INSTRUCTION_ACCESS_DISABLE;
  MPU_InitStruct.IsShareable = MPU_ACCESS_SHAREABLE;
  MPU_InitStruct.IsCacheable = MPU_ACCESS_NOT_CACHEABLE;
  MPU_InitStruct.IsBufferable = MPU_ACCESS_NOT_BUFFERABLE;

  HAL_MPU_ConfigRegion(&MPU_InitStruct);
  /* Enables the MPU */
  HAL_MPU_Enable(MPU_PRIVILEGED_DEFAULT);

}

void Error_Handler(void)
{
  __disable_irq();
  while (1)
  {
  }
}
